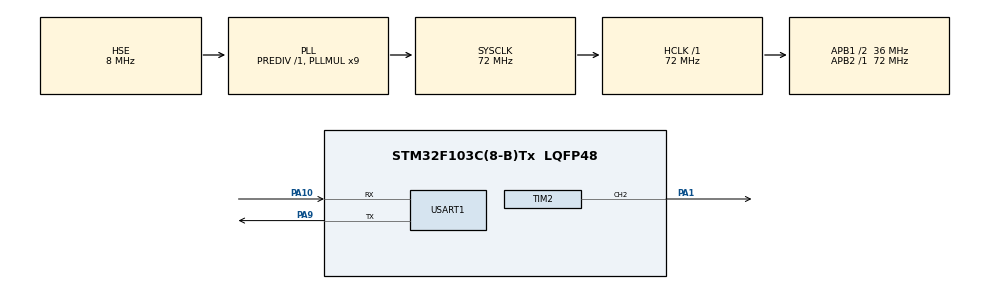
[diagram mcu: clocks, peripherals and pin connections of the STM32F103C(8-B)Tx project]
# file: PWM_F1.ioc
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Mcu.Family=STM32F1
Mcu.Name=STM32F103C(8-B)Tx
Mcu.Package=LQFP48
NVIC.PriorityGroup=NVIC_PRIORITYGROUP_4
PA1.Signal=S_TIM2_CH2
PA10.Mode=Asynchronous
PA10.Signal=USART1_RX
PA13.Mode=Serial_Wire
PA13.Signal=SYS_JTMS-SWDIO
PA14.Mode=Serial_Wire
PA14.Signal=SYS_JTCK-SWCLK
PA9.Mode=Asynchronous
PA9.Signal=USART1_TX
PC14-OSC32_IN.Mode=LSE-External-Oscillator
PC14-OSC32_IN.Signal=RCC_OSC32_IN
PC15-OSC32_OUT.Mode=LSE-External-Oscillator
PC15-OSC32_OUT.Signal=RCC_OSC32_OUT
PD0-OSC_IN.Mode=HSE-External-Oscillator
PD0-OSC_IN.Signal=RCC_OSC_IN
PD1-OSC_OUT.Mode=HSE-External-Oscillator
PD1-OSC_OUT.Signal=RCC_OSC_OUT
ProjectManager.HeapSize=0x200
ProjectManager.StackSize=0x400
ProjectManager.TargetToolchain=MDK-ARM V5.32
RCC.AHBFreq_Value=72000000
RCC.APB1CLKDivider=RCC_HCLK_DIV2
RCC.APB1Freq_Value=36000000
RCC.APB1TimFreq_Value=72000000
RCC.APB2Freq_Value=72000000
RCC.APB2TimFreq_Value=72000000
RCC.HCLKFreq_Value=72000000
RCC.PLLMUL=RCC_PLL_MUL9
RCC.PLLSourceVirtual=RCC_PLLSOURCE_HSE
RCC.SYSCLKFreq_VALUE=72000000
RCC.SYSCLKSource=RCC_SYSCLKSOURCE_PLLCLK
RCC.USBFreq_Value=72000000
SH.S_TIM2_CH2.0=TIM2_CH2,PWM Generation2 CH2
TIM2.AutoReloadPreload=TIM_AUTORELOAD_PRELOAD_ENABLE
TIM2.Channel-PWM\ Generation2\ CH2=TIM_CHANNEL_2
TIM2.Period=100-1
TIM2.Prescaler=36-1
TIM2.Pulse-PWM\ Generation2\ CH2=50-1
USART1.VirtualMode=VM_ASYNC
VP_TIM2_VS_ClockSourceINT.Mode=Internal
board=custom

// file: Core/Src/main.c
/* USER CODE BEGIN Header */
/**
  ******************************************************************************
  * @file           : main.c
  * @brief          : Main program body
  ******************************************************************************
  * @attention
  *
  * Copyright (c) 2026 STMicroelectronics.
  * All rights reserved.
  *
  * This software is licensed under terms that can be found in the LICENSE file
  * in the root directory of this software component.
  * If no LICENSE file comes with this software, it is provided AS-IS.
  *
  ******************************************************************************
  */
/* USER CODE END Header */
#include "main.h"
#include "tim.h"
#include "usart.h"
#include "gpio.h"

/* USER CODE BEGIN Includes */
#include <stdlib.h>
#include <string.h>
/* USER CODE END Includes */

/* USER CODE BEGIN PV */
static uint8_t rx_buf[UART_RX_BUF_SIZE];
/* USER CODE END PV */

void SystemClock_Config(void);
/* USER CODE BEGIN PFP */
void PWM_SetFrequency(uint32_t freq_hz);
/* USER CODE END PFP */

/* USER CODE BEGIN 0 */

/* 设置PWM频率(Hz)并保�?0%占空�?*/
void PWM_SetFrequency(uint32_t freq_hz)
{
    /* TIM2时钟 = APB1*2 = 72MHz (APB1预分�?1时定时器时钟翻�? */
    uint32_t tim_clk = HAL_RCC_GetPCLK1Freq() * 2;
    uint32_t psc, arr;

    if (freq_hz < 1)  freq_hz = 1;
    if (freq_hz > 300000) freq_hz = 300000;

    /* 目标ARR�?99，保证占空比调节精度 */
    if (tim_clk / (freq_hz * 1000) > 0) {
        psc = tim_clk / (freq_hz * 1000) - 1;
    } else {
        psc = 0;
    }
    if (psc > 65535) psc = 65535;

    arr = tim_clk / ((psc + 1) * freq_hz) - 1;

    if (arr > 65535) {
        arr = 65535;
        psc = tim_clk / ((arr + 1) * freq_hz) - 1;
        if (psc > 65535) psc = 65535;
    }
    if (arr < 10) arr = 10;

    HAL_TIM_PWM_Stop(&htim2, TIM_CHANNEL_2);
    __HAL_TIM_SET_PRESCALER(&htim2, psc);
    __HAL_TIM_SET_AUTORELOAD(&htim2, arr);
    __HAL_TIM_SET_COMPARE(&htim2, TIM_CHANNEL_2, (arr + 1) / 2);
    HAL_TIM_PWM_Start(&htim2, TIM_CHANNEL_2);
}
/* USER CODE END 0 */

int main(void)
{

  /* MCU Configuration--------------------------------------------------------*/

  /* Reset of all peripherals, Initializes the Flash interface and the Systick. */
  HAL_Init();

  /* Configure the system clock */
  SystemClock_Config();

  /* Initialize all configured peripherals */
  MX_GPIO_Init();
  MX_TIM2_Init();
  MX_USART1_UART_Init();
  /* USER CODE BEGIN 2 */
  HAL_TIM_PWM_Start(&htim2, TIM_CHANNEL_2);   /* 启动PA1 PWM输出，默�?0kHz/50% */
	PWM_SetFrequency(10);
  /* USER CODE END 2 */

  /* Infinite loop */
  while (1)
  {

    /* USER CODE BEGIN 3 */
    if (uart_rx_done) {
        uint8_t len = uart_rx_frame_len;
        memcpy(rx_buf, (void *)uart_rx_frame, len);
        rx_buf[len] = '\0';
        int32_t freq = atoi((char *)rx_buf);
        if (freq >= 1 && freq <= 300000) {
            PWM_SetFrequency((uint32_t)freq);
        }
        uart_rx_done = 0;
    }
  }
  /* USER CODE END 3 */
}

void SystemClock_Config(void)
{
  RCC_OscInitTypeDef RCC_OscInitStruct = {0};
  RCC_ClkInitTypeDef RCC_ClkInitStruct = {0};

  /** Initializes the RCC Oscillators according to the specified parameters
  * in the RCC_OscInitTypeDef structure.
  */
  RCC_OscInitStruct.OscillatorType = RCC_OSCILLATORTYPE_HSE;
  RCC_OscInitStruct.HSEState = RCC_HSE_ON;
  RCC_OscInitStruct.HSEPredivValue = RCC_HSE_PREDIV_DIV1;
  RCC_OscInitStruct.HSIState = RCC_HSI_ON;
  RCC_OscInitStruct.PLL.PLLState = RCC_PLL_ON;
  RCC_OscInitStruct.PLL.PLLSource = RCC_PLLSOURCE_HSE;
  RCC_OscInitStruct.PLL.PLLMUL = RCC_PLL_MUL9;
  if (HAL_RCC_OscConfig(&RCC_OscInitStruct) != HAL_OK)
  {
    Error_Handler();
  }

  /** Initializes the CPU, AHB and APB buses clocks
  */
  RCC_ClkInitStruct.ClockType = RCC_CLOCKTYPE_HCLK|RCC_CLOCKTYPE_SYSCLK
                              |RCC_CLOCKTYPE_PCLK1|RCC_CLOCKTYPE_PCLK2;
  RCC_ClkInitStruct.SYSCLKSource = RCC_SYSCLKSOURCE_PLLCLK;
  RCC_ClkInitStruct.AHBCLKDivider = RCC_SYSCLK_DIV1;
  RCC_ClkInitStruct.APB1CLKDivider = RCC_HCLK_DIV2;
  RCC_ClkInitStruct.APB2CLKDivider = RCC_HCLK_DIV1;

  if (HAL_RCC_ClockConfig(&RCC_ClkInitStruct, FLASH_LATENCY_2) != HAL_OK)
  {
    Error_Handler();
  }
}

void Error_Handler(void)
{
  __disable_irq();
  while (1)
  {
  }
}
